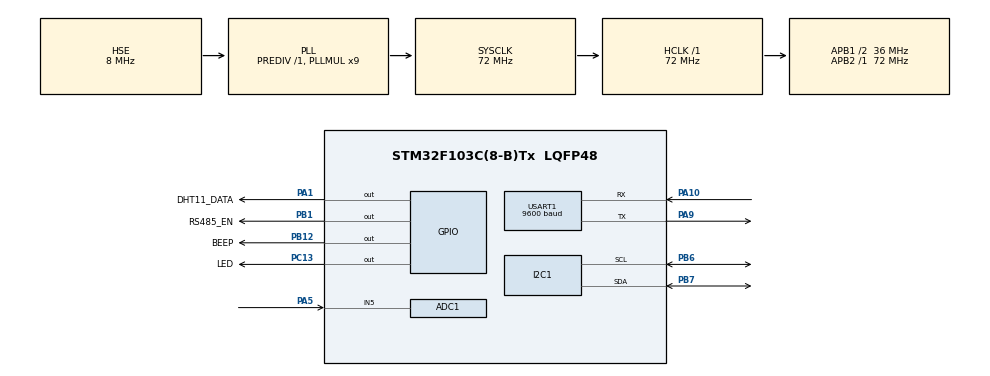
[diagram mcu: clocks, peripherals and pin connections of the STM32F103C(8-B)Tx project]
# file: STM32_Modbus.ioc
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ADC1.Channel-0\#ChannelRegularConversion=ADC_CHANNEL_5
ADC1.NbrOfConversionFlag=1
ADC1.Rank-0\#ChannelRegularConversion=1
ADC1.SamplingTime-0\#ChannelRegularConversion=ADC_SAMPLETIME_1CYCLE_5
ADC1.master=1
Dma.Request0=USART1_RX
Dma.Request1=USART1_TX
Dma.USART1_RX.0.Direction=DMA_PERIPH_TO_MEMORY
Dma.USART1_RX.0.Instance=DMA1_Channel5
Dma.USART1_RX.0.MemDataAlignment=DMA_MDATAALIGN_BYTE
Dma.USART1_RX.0.MemInc=DMA_MINC_ENABLE
Dma.USART1_RX.0.Mode=DMA_NORMAL
Dma.USART1_RX.0.PeriphDataAlignment=DMA_PDATAALIGN_BYTE
Dma.USART1_RX.0.PeriphInc=DMA_PINC_DISABLE
Dma.USART1_RX.0.Priority=DMA_PRIORITY_LOW
Dma.USART1_TX.1.Direction=DMA_MEMORY_TO_PERIPH
Dma.USART1_TX.1.Instance=DMA1_Channel4
Dma.USART1_TX.1.MemDataAlignment=DMA_MDATAALIGN_BYTE
Dma.USART1_TX.1.MemInc=DMA_MINC_ENABLE
Dma.USART1_TX.1.Mode=DMA_NORMAL
Dma.USART1_TX.1.PeriphDataAlignment=DMA_PDATAALIGN_BYTE
Dma.USART1_TX.1.PeriphInc=DMA_PINC_DISABLE
Dma.USART1_TX.1.Priority=DMA_PRIORITY_LOW
I2C1.I2C_Mode=I2C_Standard
Mcu.Family=STM32F1
Mcu.Name=STM32F103C(8-B)Tx
Mcu.Package=LQFP48
NVIC.DMA1_Channel4_IRQn=true\:0\:0\:false\:false\:true\:false\:true\:true
NVIC.DMA1_Channel5_IRQn=true\:0\:0\:false\:false\:true\:false\:true\:true
NVIC.PriorityGroup=NVIC_PRIORITYGROUP_4
NVIC.USART1_IRQn=true\:0\:0\:false\:false\:true\:true\:true\:true
PA1.GPIO_Label=DHT11_DATA
PA1.Signal=GPIO_Output
PA10.Mode=Asynchronous
PA10.Signal=USART1_RX
PA13.Mode=Serial_Wire
PA13.Signal=SYS_JTMS-SWDIO
PA14.Mode=Serial_Wire
PA14.Signal=SYS_JTCK-SWCLK
PA5.Signal=ADCx_IN5
PA9.Mode=Asynchronous
PA9.Signal=USART1_TX
PB1.GPIO_Label=RS485_EN
PB1.Signal=GPIO_Output
PB12.GPIO_Label=BEEP
PB12.PinState=GPIO_PIN_SET
PB12.Signal=GPIO_Output
PB6.Mode=I2C
PB6.Signal=I2C1_SCL
PB7.Mode=I2C
PB7.Signal=I2C1_SDA
PC13-TAMPER-RTC.GPIO_Label=LED
PC13-TAMPER-RTC.Signal=GPIO_Output
PC14-OSC32_IN.Mode=LSE-External-Oscillator
PC14-OSC32_IN.Signal=RCC_OSC32_IN
PC15-OSC32_OUT.Mode=LSE-External-Oscillator
PC15-OSC32_OUT.Signal=RCC_OSC32_OUT
PD0-OSC_IN.Mode=HSE-External-Oscillator
PD0-OSC_IN.Signal=RCC_OSC_IN
PD1-OSC_OUT.Mode=HSE-External-Oscillator
PD1-OSC_OUT.Signal=RCC_OSC_OUT
ProjectManager.HeapSize=0x200
ProjectManager.StackSize=0x400
ProjectManager.TargetToolchain=MDK-ARM V5.32
RCC.ADCPresc=RCC_ADCPCLK2_DIV6
RCC.AHBFreq_Value=72000000
RCC.APB1CLKDivider=RCC_HCLK_DIV2
RCC.APB1Freq_Value=36000000
RCC.APB1TimFreq_Value=72000000
RCC.APB2Freq_Value=72000000
RCC.APB2TimFreq_Value=72000000
RCC.HCLKFreq_Value=72000000
RCC.PLLMUL=RCC_PLL_MUL9
RCC.PLLSourceVirtual=RCC_PLLSOURCE_HSE
RCC.SYSCLKFreq_VALUE=72000000
RCC.SYSCLKSource=RCC_SYSCLKSOURCE_PLLCLK
RCC.USBFreq_Value=72000000
SH.ADCx_IN5.0=ADC1_IN5,IN5
TIM3.Prescaler=71
USART1.BaudRate=9600
USART1.VirtualMode=VM_ASYNC
VP_TIM3_VS_ClockSourceINT.Mode=Internal
board=custom

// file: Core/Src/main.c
/* USER CODE BEGIN Header */
/**
  ******************************************************************************
  * @file           : main.c
  * @brief          : Main program body
  ******************************************************************************
  * @attention
  *
  * Copyright (c) 2026 STMicroelectronics.
  * All rights reserved.
  *
  * This software is licensed under terms that can be found in the LICENSE file
  * in the root directory of this software component.
  * If no LICENSE file comes with this software, it is provided AS-IS.
  *
  ******************************************************************************
  */
/* USER CODE END Header */
#include "main.h"
#include "adc.h"
#include "dma.h"
#include "i2c.h"
#include "tim.h"
#include "usart.h"
#include "gpio.h"

/* USER CODE BEGIN Includes */
/*OLED测试代码
#include "oled.h"
*/

#include <stdio.h>
#include <string.h>
#include "dht11.h"
/* USER CODE END Includes */

/* USER CODE BEGIN PV */
uint8_t Receive_Data[2] = {0};
uint8_t Send_Data[2] = {0};
/* USER CODE END PV */

void SystemClock_Config(void);

/* USER CODE BEGIN 0 */
void HAL_UART_RxCpltCallback(UART_HandleTypeDef *huart)
{
  HAL_GPIO_TogglePin(LED_GPIO_Port, LED_Pin); // 切换LED状态
    if (huart->Instance == USART1) {
        Send_Data[0] = Receive_Data[0];
        Send_Data[1] = Receive_Data[1];
        HAL_UART_Transmit_DMA(&huart1, Send_Data, 2); // 接收数据后立即回传
    }
    HAL_UART_Receive_DMA(&huart1, Receive_Data, 2);// 接收数据，使用DMA方式
}
/* USER CODE END 0 */

int main(void)
{

  /* MCU Configuration--------------------------------------------------------*/

  /* Reset of all peripherals, Initializes the Flash interface and the Systick. */
  HAL_Init();

  /* Configure the system clock */
  SystemClock_Config();

  /* Initialize all configured peripherals */
  MX_GPIO_Init();
  MX_DMA_Init();
  MX_I2C1_Init();
  MX_ADC1_Init();
  MX_USART1_UART_Init();
  MX_TIM3_Init();
  /* USER CODE BEGIN 2 */
  /*OLED测试代码
  HAL_Delay(20);
  OLED_Init();
  */

  /*ADC测试代码
  int value = 0;
  float voltage = 0.0;
  char message[20] = "";
  HAL_ADCEx_Calibration_Start(&hadc1); // 校准ADC
  */

  /*DHT11测试代码
  HAL_TIM_Base_Start(&htim3); // 启动定时器用于微秒级延时
  char message[50] = "";
  DHT11_Data_TypeDef DHT11_Data;
  HAL_Delay(2000); // 等待传感器稳定
  */
  /*串口接收测试代码*/
  HAL_UART_Receive_DMA(&huart1, Receive_Data, 2);// 接收数据，使用DMA方式

  /* USER CODE END 2 */

  /* Infinite loop */
  /* USER CODE BEGIN WHILE */
  while (1)
  {
    /*OLED测试代码
    OLED_NewFrame();
    OLED_PrintString(0, 0, "Hello, World!", &font16x16, OLED_COLOR_NORMAL);
    OLED_ShowFrame();
    */

    /*ADC测试代码
    HAL_ADC_Start(&hadc1);
    HAL_ADC_PollForConversion(&hadc1, HAL_MAX_DELAY);
    value = HAL_ADC_GetValue(&hadc1);
    voltage = (value / 4096.0f) * 3.3f;// 假设使用12位ADC，参考电压为3.3V
    sprintf(message, "ADC Value: %d, Voltage: %.2fV\r\n", value, voltage);
    HAL_UART_Transmit(&huart1, (uint8_t*)message, strlen(message), HAL_MAX_DELAY);
    HAL_Delay(1000); // 每1秒读取一次ADC值
    */

    //功能测试
    // HAL_GPIO_TogglePin(LED_GPIO_Port, LED_Pin); // 切换LED状态
    // HAL_Delay(1000); // 每1秒切换一次LED状态
    // HAL_UART_Transmit(&huart1, (uint8_t*)"LED Toggled\r\n", 14, HAL_MAX_DELAY); // 发送LED状态切换消息

    /*DHT11测试代码
    if(!DHT11_Read_TempAndHumidity(&DHT11_Data)) {
      sprintf(message, "Temperature: %.1fC, Humidity: %.1f%%\r\n", DHT11_Data.temperature, DHT11_Data.humidity);
      HAL_UART_Transmit(&huart1, (uint8_t*)message, strlen(message), HAL_MAX_DELAY);
    } else {
      sprintf(message, "Failed to read from DHT11\r\n");
      HAL_UART_Transmit(&huart1, (uint8_t*)message, strlen(message), HAL_MAX_DELAY);
    }
      HAL_Delay(1000); // 每2秒读取一次DHT11数据
    */
    /*串口接收测试代码*/

    /* USER CODE END WHILE */

  }
}

void SystemClock_Config(void)
{
  RCC_OscInitTypeDef RCC_OscInitStruct = {0};
  RCC_ClkInitTypeDef RCC_ClkInitStruct = {0};
  RCC_PeriphCLKInitTypeDef PeriphClkInit = {0};

  /** Initializes the RCC Oscillators according to the specified parameters
  * in the RCC_OscInitTypeDef structure.
  */
  RCC_OscInitStruct.OscillatorType = RCC_OSCILLATORTYPE_HSE;
  RCC_OscInitStruct.HSEState = RCC_HSE_ON;
  RCC_OscInitStruct.HSEPredivValue = RCC_HSE_PREDIV_DIV1;
  RCC_OscInitStruct.HSIState = RCC_HSI_ON;
  RCC_OscInitStruct.PLL.PLLState = RCC_PLL_ON;
  RCC_OscInitStruct.PLL.PLLSource = RCC_PLLSOURCE_HSE;
  RCC_OscInitStruct.PLL.PLLMUL = RCC_PLL_MUL9;
  if (HAL_RCC_OscConfig(&RCC_OscInitStruct) != HAL_OK)
  {
    Error_Handler();
  }

  /** Initializes the CPU, AHB and APB buses clocks
  */
  RCC_ClkInitStruct.ClockType = RCC_CLOCKTYPE_HCLK|RCC_CLOCKTYPE_SYSCLK
                              |RCC_CLOCKTYPE_PCLK1|RCC_CLOCKTYPE_PCLK2;
  RCC_ClkInitStruct.SYSCLKSource = RCC_SYSCLKSOURCE_PLLCLK;
  RCC_ClkInitStruct.AHBCLKDivider = RCC_SYSCLK_DIV1;
  RCC_ClkInitStruct.APB1CLKDivider = RCC_HCLK_DIV2;
  RCC_ClkInitStruct.APB2CLKDivider = RCC_HCLK_DIV1;

  if (HAL_RCC_ClockConfig(&RCC_ClkInitStruct, FLASH_LATENCY_2) != HAL_OK)
  {
    Error_Handler();
  }
  PeriphClkInit.PeriphClockSelection = RCC_PERIPHCLK_ADC;
  PeriphClkInit.AdcClockSelection = RCC_ADCPCLK2_DIV6;
  if (HAL_RCCEx_PeriphCLKConfig(&PeriphClkInit) != HAL_OK)
  {
    Error_Handler();
  }
}

void Error_Handler(void)
{
  __disable_irq();
  while (1)
  {
  }
}
